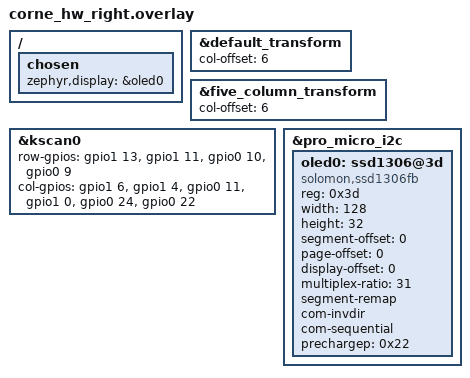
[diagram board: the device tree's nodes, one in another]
/*
 * Copyright (c) 2020 The ZMK Contributors
 *
 * SPDX-License-Identifier: MIT
 */

#include <dt-bindings/pinctrl/nrf-pinctrl.h>
#include <dt-bindings/i2c/i2c.h>
#include "corne_hw.dtsi"

&default_transform {
    col-offset = <6>;
};

&five_column_transform {
    col-offset = <6>;
};

&kscan0 {
    row-gpios = <&gpio1 13 GPIO_ACTIVE_HIGH>,  /* Row 0 = P1.13 (as physically wired) */
                <&gpio1 11 GPIO_ACTIVE_HIGH>,  /* Row 1 = P1.11 (as physically wired) */
                <&gpio0 10 GPIO_ACTIVE_HIGH>,  /* Row 2 = P0.10 */
                <&gpio0 9  GPIO_ACTIVE_HIGH>;  /* Row 3 = P0.09 */

    col-gpios = <&gpio1 6  (GPIO_ACTIVE_HIGH | GPIO_PULL_DOWN)>,  /* Col 0 = P1.06 */
                <&gpio1 4  (GPIO_ACTIVE_HIGH | GPIO_PULL_DOWN)>,  /* Col 1 = P1.04 */
                <&gpio0 11 (GPIO_ACTIVE_HIGH | GPIO_PULL_DOWN)>,  /* Col 2 = P0.11 */
                <&gpio1 0  (GPIO_ACTIVE_HIGH | GPIO_PULL_DOWN)>,  /* Col 3 = P1.00 */
                <&gpio0 24 (GPIO_ACTIVE_HIGH | GPIO_PULL_DOWN)>,  /* Col 4 = P0.24 */
                <&gpio0 22 (GPIO_ACTIVE_HIGH | GPIO_PULL_DOWN)>;  /* Col 5 = P0.22 */
};

/ {
    chosen {
        zephyr,display = &oled0;
    };
};

// OLED configuration - using pro_micro_i2c on Nice Nano (same as working left side)
// Pins: SDA=P0.17, SCL=P0.20 (board defaults)
&pro_micro_i2c {
    status = "okay";

    oled0: ssd1306@3d {
        compatible = "solomon,ssd1306fb";
        reg = <0x3d>;
        width = <128>;
        height = <32>;
        segment-offset = <0>;
        page-offset = <0>;
        display-offset = <0>;
        multiplex-ratio = <31>;
        segment-remap;
        com-invdir;
        com-sequential;
        prechargep = <0x22>;
    };
};

// pinctrl configuration is handled by the board (Nice Nano)

